# APM32F403 register map
File version: 1.0
CPU: CM4 r1p0, little endian, no MPU, no FPU, 4 interrupt priority bits
Registers are 32-bit, read-write, reset 0x0 unless marked. A register's access mark holds for its fields unless they carry their own. Offsets are from the block's base; [hi:lo] are bit positions.

## PMU — Power control
Base 0x40007000
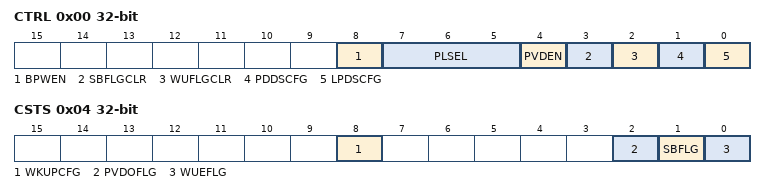
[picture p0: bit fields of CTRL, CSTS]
0x00 CTRL — power control register
  [8] BPWEN — Disable backup domain write protection
  [7:5] PLSEL — PVD level selection
  [4] PVDEN — Power voltage detector enable
  [3] SBFLGCLR — Clear standby flag
  [2] WUFLGCLR — Clear wakeup flag
  [1] PDDSCFG — Power down deepsleep
  [0] LPDSCFG — Low-power deep sleep
0x04 CSTS access per field — power control/status register
  [8] WKUPCFG rw — Enable WKUP pin
  [2] PVDOFLG ro — PVD output
  [1] SBFLG ro — Standby flag
  [0] WUEFLG ro — Wakeup flag

## I2C1 — Inter-integrated circuit
Base 0x40005400
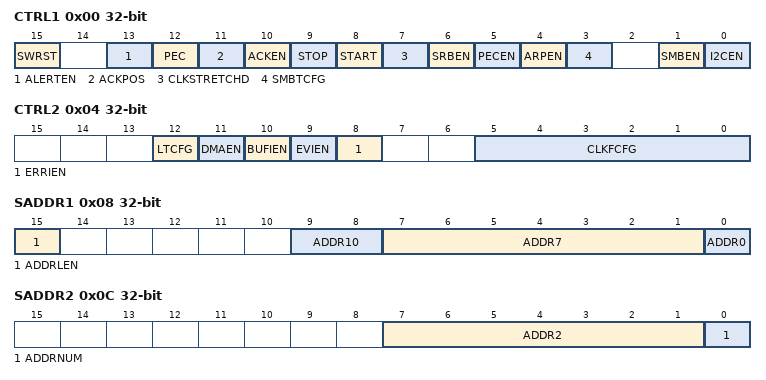
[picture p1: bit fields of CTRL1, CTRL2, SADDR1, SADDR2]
0x00 CTRL1 — Control register 1
  [15] SWRST — Software reset
  [13] ALERTEN — SMBus alert
  [12] PEC — Packet error checking
  [11] ACKPOS — Acknowledge/PEC Position (for data reception)
  [10] ACKEN — Acknowledge enable
  [9] STOP — Stop generation
  [8] START — Start generation
  [7] CLKSTRETCHD — Clock stretching disable (Slave mode)
  [6] SRBEN — General call enable
  [5] PECEN — PEC enable
  [4] ARPEN — ARP enable
  [3] SMBTCFG — SMBus type
  [1] SMBEN — SMBus mode
  [0] I2CEN — I2C enable
0x04 CTRL2 — Control register 2
  [12] LTCFG — DMA last transfer
  [11] DMAEN — DMA requests enable
  [10] BUFIEN — Buffer interrupt enable
  [9] EVIEN — Event interrupt enable
  [8] ERRIEN — Error interrupt enable
  [5:0] CLKFCFG — I2C clock frequency
0x08 SADDR1 — Own address register 1
  [15] ADDRLEN — Addressing mode (slave mode)
  [9:8] ADDR10 — Interface address
  [7:1] ADDR7 — Interface address
  [0] ADDR0 — Interface address
0x0C SADDR2 — Own address register 2
  [7:1] ADDR2 — Interface address
  [0] ADDRNUM — Slave Address Number Configure
0x10 DATA
  [7:0] DATA — 8-bit data register
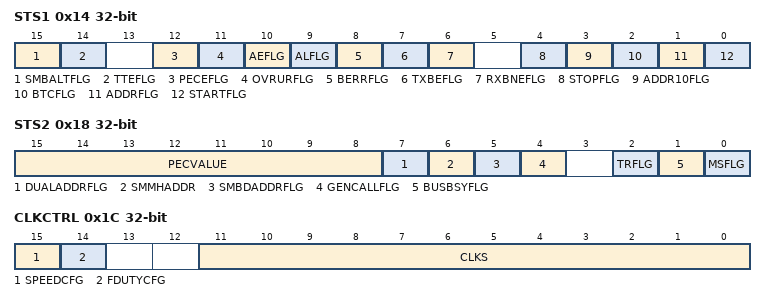
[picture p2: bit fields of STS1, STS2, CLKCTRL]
0x14 STS1 access per field — Status register 1
  [15] SMBALTFLG rw — SMBus alert
  [14] TTEFLG rw — Timeout or Tlow error
  [12] PECEFLG rw — PEC Error in reception
  [11] OVRURFLG rw — Overrun/Underrun
  [10] AEFLG rw — Acknowledge failure
  [9] ALFLG rw — Arbitration lost (master mode)
  [8] BERRFLG rw — Bus error
  [7] TXBEFLG ro — Data register empty (transmitters)
  [6] RXBNEFLG ro — Data register not empty (receivers)
  [4] STOPFLG ro — Stop detection (slave mode)
  [3] ADDR10FLG ro — 10-bit header sent (Master mode)
  [2] BTCFLG ro — Byte transfer finished
  [1] ADDRFLG ro — Address sent (master mode)/matched (slave mode)
  [0] STARTFLG ro — Start bit (Master mode)
0x18 STS2 ro — Status register 2
  [15:8] PECVALUE — Save Packet Error Checking Value
  [7] DUALADDRFLG — Dual flag (Slave mode)
  [6] SMMHADDR — SMBus host header (Slave mode)
  [5] SMBDADDRFLG — SMBus device default address (Slave mode)
  [4] GENCALLFLG — General call address (Slave mode)
  [2] TRFLG — Transmitter/receiver
  [1] BUSBSYFLG — Bus busy
  [0] MSFLG — Master Slave Mode Flag
0x1C CLKCTRL — Clock control register
  [15] SPEEDCFG — Master Mode Speed Configure
  [14] FDUTYCFG — Fast mode duty cycle
  [11:0] CLKS — Clock control register in Fast/Standard mode (Master mode)
0x20 RISETMAX reset 0x2 — Maximum Rise Time register
  [5:0] RISETMAX — Maximum rise time in Fast/Standard mode (Master mode)

## IWDT — Independent watchdog
Base 0x40003000
0x00 KEY wo
  [15:0] KEY — Key value (write only, read 0000h)
0x04 PSC — Prescaler register
  [2:0] PSC — Prescaler divider
0x08 CNTRLD reset 0xFFF — Reload register
  [11:0] CNTRLD — Watchdog counter reload value
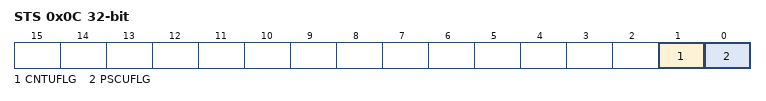
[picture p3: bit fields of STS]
0x0C STS ro — Status register
  [1] CNTUFLG — Watchdog counter reload value update
  [0] PSCUFLG — Watchdog prescaler value update

## WWDT — Window watchdog
Base 0x40002C00
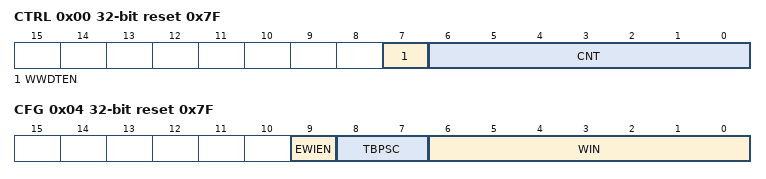
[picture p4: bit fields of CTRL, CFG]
0x00 CTRL reset 0x7F — Control register
  [7] WWDTEN — Activation bit
  [6:0] CNT — 7-bit counter (MSB to LSB)
0x04 CFG reset 0x7F — Configuration register
  [9] EWIEN — Early wakeup interrupt
  [8:7] TBPSC — Timer Base Prescaler Factor Configure
  [6:0] WIN — 7-bit window value
0x08 STS — Status register
  [0] EWIFLG — Early wakeup interrupt flag
